# DFTSS_1.0 register map
Vendor: Texas Instruments
Peripheral module from a debugger description file (folder mspm33c321x).
Registers are 32-bit, read-write, no defined reset value unless marked. A register's access mark holds for its fields unless they carry their own. Offsets are as the file gives them; lines under a group give offsets from that group; [hi:lo] are bit positions; {n}, {i} and the like mark numbered series; 'fields as' and 'values as' point back to an identical list; <NAME> marks a mode.

## DFTSS
0x04 DFTSS_PINCM group
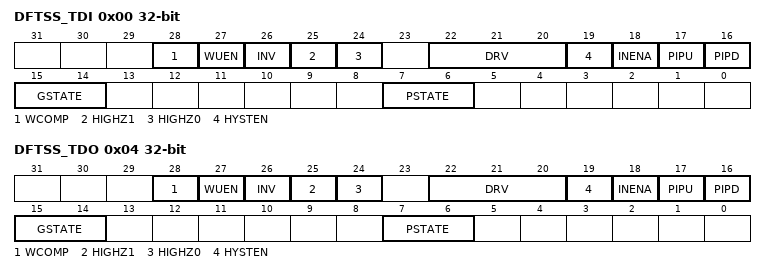
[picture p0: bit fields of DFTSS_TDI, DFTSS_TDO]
  0x00 DFTSS_TDI — TDI
    [28] WCOMP — Wake up compare value
      0=MATCH_ZERO (Match 0 will wake); 1=MATCH_ONE (Match 1 will wake)
    [27] WUEN — Wake up enable
      0=NO_WAKEUP (Wake up not enabled); 1=WAKEUP (Wake up enabled)
    [26] INV — Invert digital input/output relative to peripheral/GPIO
      0=NO_CHNG (Input and output are non-inverted); 1=CHNG (Input and output are inverted)
    [25] HIGHZ1 — High-Z instead of high output
      0=DRV_HIGH (Pin can be driven high); 1=DRV_HIZ (Pin is tri-stated instead of driven high)
    [24] HIGHZ0 — High-Z instead of low output
      0=DRV_LOW (Pin can be driven low); 1=DRV_HIZ (Pin is tri-stated instead of driven low)
    [22:20] DRV — Drive strength options
      0=STRENGTH_0 (Lowest drive strength); {v}=STRENGTH_{v} (Drive strength {v+1}/8) (v=1..6); 7=STRENGTH_7 (Highest drive strength)
    [19] HYSTEN — Hysteresis enable
      0=DIS_HYST (No hysteresis); 1=EN_HYST (Hysteresis on)
    [18] INENA — Input enable
      0=INP_DISABLE (Inputs 0 to connected core); 1=INP_ENABLE (Inputs IO pad value to connected core)
    [17] PIPU — Pull up enable
      0=NO_PULL_UP; 1=PULL_UP
    [16] PIPD — Pull down enable
      0=NO_PULL_DOWN; 1=PULL_DOWN
    [15:14] GSTATE — GPIO Channel State
      0=UNASSIGNED (G-Channel is in Unassigned State); 1=HANDOVER (G-Channel is in Handover State); 2=CONC_NOT_LOCKED (G-Channel is in Connected State and not Locked (That is F field is allowed to change without going back through Unassigned state)); 3=CONC_LOCKED (G-Channel is in Connected State and Locked (That is F field is not allowed to change to a different non-Zero value until both G and P channels go to Unassigned))
    [7:6] PSTATE — Peripheral-Analog Channel State
      0=UNASSIGNED (P-Channel is in Unassigned State); 1=HANDOVER (P-Channel is in Handover State); 2=CONC_NOT_LOCKED (P-Channel is in Connected State and not Locked (That is F field is allowed to change without going back through Unassigned state)); 3=CONC_LOCKED (P-Channel is in Connected State and Locked (That is F field is not allowed to change to a different non-Zero value until both G and P channels go to Unassigned))
  0x04 DFTSS_TDO — TDO
    fields as DFTSS_PINCM.DFTSS_TDI
